# CY8C5888LTQ_LP097 register map
File version: 0.1
CY8C58LP
Registers are 8-bit, read-write, no defined reset value unless marked. A register's access mark holds for its fields unless they carry their own. Offsets are from the block's base; lines under a group give offsets from that group; [hi:lo] are bit positions; {n}, {i} and the like mark numbered series; 'fields as' and 'values as' point back to an identical list; <NAME> marks a mode.

## Memory map
0x00000000 Engine_Mode_FL
0x00000000 QuadDec_RL
0x00000000 QuadDec_RL_Cnt16
0x00000000 XBee — UART
0x00000000 Engine_Mode_RL
0x00000000 QuadDec_RR
0x00000000 QuadDec_RR_Cnt16
0x00000000 ENGINE_OnOff
0x00000000 UART_LOG — UART
0x00000000 Engine_PWM_Rear
0x00000000 Engine_PWM_Front
0x00000000 Engine_Mode_FR
0x00000000 QuadDec_FR
0x00000000 QuadDec_FR_Cnt16
0x00000000 QuadDec_FL
0x00000000 QuadDec_FL_Cnt16
0x00000000 Engine_Mode_RR

## Engine_Mode_FL
Base 0x00000000
0x4000657A Engine_Mode_FL_CONTROL_REG

## QuadDec_RL
Base 0x00000000
0x40006504 QuadDec_RL_Cnt16_COUNTER 16-bit — Counter value
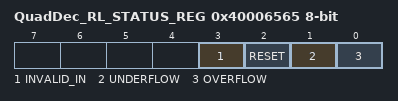
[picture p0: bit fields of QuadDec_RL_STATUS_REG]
0x40006565 QuadDec_RL_STATUS_REG — Quadrature Decoder Status Register
  [3] INVALID_IN ro — Invalid state transition on the A and B inputs
  [2] RESET ro — Counter Reset due index
  [1] UNDERFLOW ro — Counter underflow
  [0] OVERFLOW ro — Counter overflow

## QuadDec_RL_Cnt16
Base 0x00000000; alternate view of QuadDec_RL
0x40006504 QuadDec_RL_Cnt16_COUNTER 16-bit — UDB.A0 - Current Counter Value
0x40006524 QuadDec_RL_Cnt16_PERIOD 16-bit — UDB.D0 - Assigned Period
0x40006534 QuadDec_RL_Cnt16_COMPARE 16-bit — UDB.D1 - Assigned Compare Value
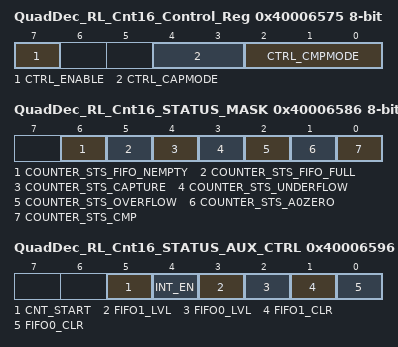
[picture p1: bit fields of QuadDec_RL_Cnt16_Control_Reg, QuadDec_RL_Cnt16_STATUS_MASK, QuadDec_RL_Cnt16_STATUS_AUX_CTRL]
0x40006575 QuadDec_RL_Cnt16_Control_Reg — UDB Control Register - Assigned Control Register Value
  [7] CTRL_ENABLE — Enable Counter
  [4:3] CTRL_CAPMODE — Capture mode
  [2:0] CTRL_CMPMODE — Compare mode
0x40006586 QuadDec_RL_Cnt16_STATUS_MASK — UDB Status bits Interrupt Mask Enable Register
  [6] COUNTER_STS_FIFO_NEMPTY — FIFO Not Empty Status
  [5] COUNTER_STS_FIFO_FULL — FIFO Full Status
  [4] COUNTER_STS_CAPTURE — Capture Status
  [3] COUNTER_STS_UNDERFLOW — Underflow status
  [2] COUNTER_STS_OVERFLOW — Overflow status
  [1] COUNTER_STS_A0ZERO — A0 Zero ouput status
  [0] COUNTER_STS_CMP — Compare output status
0x40006596 QuadDec_RL_Cnt16_STATUS_AUX_CTRL — UDB Auxilliary Control Register
  [5] CNT_START — FIFO0 clear
    0=E_CNT_START0 (Disable counter); 1=E_CNT_START1 (Enable counter)
  [4] INT_EN
    0=E_INT_EN0 (Interrupt disabled); 1=E_INT_EN1 (Interrupt enabled)
  [3] FIFO1_LVL — FIFO level
    0=E_FIFO_LVL_0 (FIFO LVL: input mode: FIFO not full; output mode: FIFO not empty); 1=E_FIFO_LVL_1 (FIFO LVL: input mode: FIFO at least 1/2 empty; output mode: FIFO at least 1/2 full)
  [2] FIFO0_LVL — FIFO level
    values as FIFO1_LVL
  [1] FIFO1_CLR — FIFO1 clear
    0=E_FIFO_CLR_0 (Normal FIFO operation); 1=E_FIFO_CLR_1 (Clear FIFO state)
  [0] FIFO0_CLR — FIFO0 clear
    values as FIFO1_CLR

## XBee — UART
Base 0x00000000
0x40006423 RX_XBee_RX_ADDRESS1 — RX Address1 Register
0x40006433 RX_XBee_RX_ADDRESS2 — RX Address2 Register
0x40006443 RX_XBee_RX_DATA — RX Data Register
0x40006444 TX_XBee_TX_DATA — TX Data Register
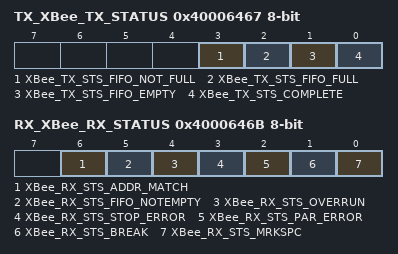
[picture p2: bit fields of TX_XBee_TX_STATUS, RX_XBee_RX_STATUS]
0x40006467 TX_XBee_TX_STATUS — TX status register
  [3] XBee_TX_STS_FIFO_NOT_FULL ro, [2] XBee_TX_STS_FIFO_FULL ro, [1] XBee_TX_STS_FIFO_EMPTY ro, [0] XBee_TX_STS_COMPLETE ro
0x4000646B RX_XBee_RX_STATUS — RX status register
  [6] XBee_RX_STS_ADDR_MATCH ro, [5] XBee_RX_STS_FIFO_NOTEMPTY ro, [4] XBee_RX_STS_OVERRUN ro, [3] XBee_RX_STS_STOP_ERROR ro, [2] XBee_RX_STS_PAR_ERROR ro, [1] XBee_RX_STS_BREAK ro, [0] XBee_RX_STS_MRKSPC ro

## Engine_Mode_RL
Base 0x00000000
0x40006471 Engine_Mode_RL_CONTROL_REG

## QuadDec_RR
Base 0x00000000
0x40006406 QuadDec_RR_Cnt16_COUNTER 16-bit — Counter value
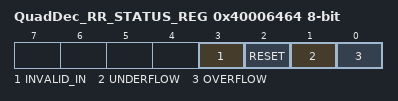
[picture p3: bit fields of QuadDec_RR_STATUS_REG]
0x40006464 QuadDec_RR_STATUS_REG — Quadrature Decoder Status Register
  [3] INVALID_IN ro — Invalid state transition on the A and B inputs
  [2] RESET ro — Counter Reset due index
  [1] UNDERFLOW ro — Counter underflow
  [0] OVERFLOW ro — Counter overflow
